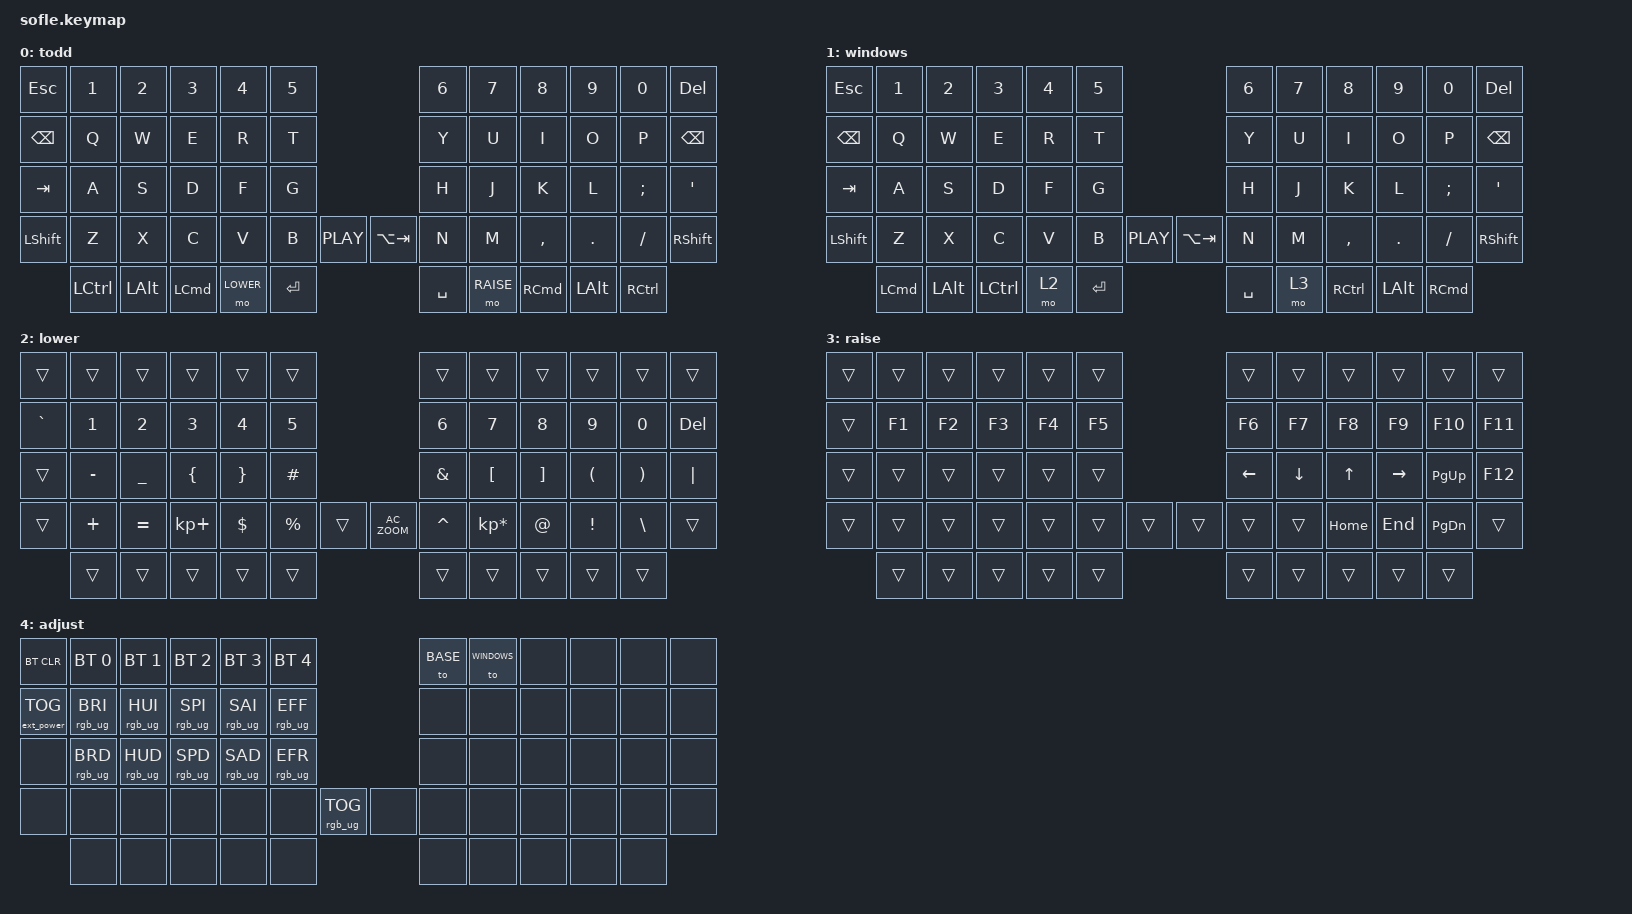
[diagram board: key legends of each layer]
/*
 * Copyright (c) 2020 The ZMK Contributors
 *
 * SPDX-License-Identifier: MIT
 */

#define BASE 0
#define WINDOWS 1
#define LOWER 2
#define RAISE 3
#define ADJUST 4

/*
 * Temporarily here because nice nano v2 spi is not defined on ZMK Yet
 * Source: https://github.com/zmkfirmware/zmk/blob/main/app/boards/shields/reviung41/boards/nice_nano.overlay
 * GitHub Issue: https://github.com/zmkfirmware/zmk/issues/885
 */

#include <dt-bindings/led/led.h>
#include <behaviors.dtsi>
#include <dt-bindings/zmk/bt.h>
#include <dt-bindings/zmk/ext_power.h>
#include <dt-bindings/zmk/keys.h>
#include <dt-bindings/zmk/rgb.h>

&pinctrl {
    spi3_default: spi3_default {
        group1 { psels = <NRF_PSEL(SPIM_MOSI, 0, 8)>; };
    };

    spi3_sleep: spi3_sleep {
        group1 {
            psels = <NRF_PSEL(SPIM_MOSI, 0, 8)>;
            low-power-enable;
        };
    };
};

&spi3 {
    compatible = "nordic,nrf-spim";
    status = "okay";
    pinctrl-0 = <&spi3_default>;
    pinctrl-1 = <&spi3_sleep>;
    pinctrl-names = "default", "sleep";

    led_strip: ws2812@0 {
        compatible = "worldsemi,ws2812-spi";
        label = "WS2812";

        /* SPI */

        reg = <0>; /* ignored, but necessary for SPI bindings */
        spi-max-frequency = <4000000>;

        /* WS2812 */

        chain-length = <30>;
        spi-one-frame = <0x70>;
        spi-zero-frame = <0x40>;
        color-mapping = <LED_COLOR_ID_GREEN LED_COLOR_ID_RED LED_COLOR_ID_BLUE>;
    };
};

/ {
    chosen { zmk,underglow = &led_strip; };
};

/* END temporary RGB support section */

/ {
    // Activate ADJUST layer by pressing raise and lower

    conditional_layers {
        compatible = "zmk,conditional-layers";

        adjust_layer {
            if-layers = <2 3>;
            then-layer = <4>;
        };
    };

    macros {
        zoomOut: zoomOut {
            compatible = "zmk,behavior-macro";
            #binding-cells = <0>;
            bindings = <&kp RIGHT_GUI &kp MINUS>;
            label = "ZOOMOUT";
        };

        zoomIn: zoomIn {
            compatible = "zmk,behavior-macro";
            #binding-cells = <0>;
            bindings = <&kp RIGHT_GUI &kp EQUAL>;
            label = "ZOOMIN";
        };
    };

    keymap {
        compatible = "zmk,keymap";

        default_layer {
            display-name = "todd";
            bindings = <
// ╭────────────────────────┬────────────────────────┬────────────────────────┬────────────────────────┬────────────────────────┬────────────────────────╮                                ╭────────────────────────┬────────────────────────┬────────────────────────┬────────────────────────┬────────────────────────┬────────────────────────╮
    &kp ESCAPE               &kp N1                   &kp N2                   &kp N3                   &kp N4                   &kp N5                                                    &kp N6                   &kp N7                   &kp N8                   &kp N9                   &kp N0                   &kp DEL
// ├────────────────────────┼────────────────────────┼────────────────────────┼────────────────────────┼────────────────────────┼────────────────────────┤                                ├────────────────────────┼────────────────────────┼────────────────────────┼────────────────────────┼────────────────────────┼────────────────────────┤
    &kp BACKSPACE            &kp Q                    &kp W                    &kp E                    &kp R                    &kp T                                                     &kp Y                    &kp U                    &kp I                    &kp O                    &kp P                    &kp BSPC
// ├────────────────────────┼────────────────────────┼────────────────────────┼────────────────────────┼────────────────────────┼────────────────────────┤                                ├────────────────────────┼────────────────────────┼────────────────────────┼────────────────────────┼────────────────────────┼────────────────────────┤
    &kp TAB                  &kp A                    &kp S                    &kp D                    &kp F                    &kp G                                                     &kp H                    &kp J                    &kp K                    &kp L                    &kp SEMI                 &kp SQT
// ├────────────────────────┼────────────────────────┼────────────────────────┼────────────────────────┼────────────────────────┼────────────────────────┤ ╭────────────╮  ╭────────────╮ ├────────────────────────┼────────────────────────┼────────────────────────┼────────────────────────┼────────────────────────┼────────────────────────┤
    &kp LSHFT                &kp Z                    &kp X                    &kp C                    &kp V                    &kp B                      &kp C_PLAY      &kp LA(TAB)    &kp N                    &kp M                    &kp COMMA                &kp DOT                  &kp FSLH                 &kp RSHFT
// ╰────────────────────────┼────────────────────────┼────────────────────────┼────────────────────────┼────────────────────────┼────────────────────────┤ ╰────────────╯  ╰────────────╯ ├────────────────────────┼────────────────────────┼────────────────────────┼────────────────────────┼────────────────────────┼────────────────────────╯
                             &kp LEFT_CONTROL         &kp LALT                 &kp LEFT_COMMAND         &mo LOWER                &kp RET                                                   &kp SPACE                &mo RAISE                &kp RIGHT_COMMAND        &kp LALT                 &kp RIGHT_CONTROL
//                          ╰────────────────────────┴────────────────────────┴────────────────────────┴────────────────────────┴────────────────────────╯                                ╰────────────────────────┴────────────────────────┴────────────────────────┴────────────────────────┴────────────────────────╯
            >;

            sensor-bindings =
                <&inc_dec_kp C_VOL_UP C_VOL_DN>,
                <&inc_dec_kp LG(LS(TAB)) LG(TAB)>;
        };

        windows {
            display-name = "windows";
            bindings = <
// ╭────────────────────────┬────────────────────────┬────────────────────────┬────────────────────────┬────────────────────────┬────────────────────────╮                                ╭────────────────────────┬────────────────────────┬────────────────────────┬────────────────────────┬────────────────────────┬────────────────────────╮
    &kp ESCAPE               &kp N1                   &kp N2                   &kp N3                   &kp N4                   &kp N5                                                    &kp N6                   &kp N7                   &kp N8                   &kp N9                   &kp N0                   &kp DEL
// ├────────────────────────┼────────────────────────┼────────────────────────┼────────────────────────┼────────────────────────┼────────────────────────┤                                ├────────────────────────┼────────────────────────┼────────────────────────┼────────────────────────┼────────────────────────┼────────────────────────┤
    &kp BACKSPACE            &kp Q                    &kp W                    &kp E                    &kp R                    &kp T                                                     &kp Y                    &kp U                    &kp I                    &kp O                    &kp P                    &kp BSPC
// ├────────────────────────┼────────────────────────┼────────────────────────┼────────────────────────┼────────────────────────┼────────────────────────┤                                ├────────────────────────┼────────────────────────┼────────────────────────┼────────────────────────┼────────────────────────┼────────────────────────┤
    &kp TAB                  &kp A                    &kp S                    &kp D                    &kp F                    &kp G                                                     &kp H                    &kp J                    &kp K                    &kp L                    &kp SEMI                 &kp SQT
// ├────────────────────────┼────────────────────────┼────────────────────────┼────────────────────────┼────────────────────────┼────────────────────────┤ ╭────────────╮  ╭────────────╮ ├────────────────────────┼────────────────────────┼────────────────────────┼────────────────────────┼────────────────────────┼────────────────────────┤
    &kp LSHFT                &kp Z                    &kp X                    &kp C                    &kp V                    &kp B                      &kp C_PLAY      &kp LA(TAB)    &kp N                    &kp M                    &kp COMMA                &kp DOT                  &kp FSLH                 &kp RSHFT
// ╰────────────────────────┼────────────────────────┼────────────────────────┼────────────────────────┼────────────────────────┼────────────────────────┤ ╰────────────╯  ╰────────────╯ ├────────────────────────┼────────────────────────┼────────────────────────┼────────────────────────┼────────────────────────┼────────────────────────╯
                             &kp LEFT_COMMAND         &kp LALT                 &kp LEFT_CONTROL         &mo 2                    &kp RET                                                   &kp SPACE                &mo 3                    &kp RIGHT_CONTROL        &kp LALT                 &kp RIGHT_COMMAND
//                          ╰────────────────────────┴────────────────────────┴────────────────────────┴────────────────────────┴────────────────────────╯                                ╰────────────────────────┴────────────────────────┴────────────────────────┴────────────────────────┴────────────────────────╯
            >;

            sensor-bindings =
                <&inc_dec_kp C_VOLUME_UP C_VOLUME_DOWN>,
                <&inc_dec_kp LA(LS(TAB)) LA(TAB)>;
        };

        LOW {
            display-name = "lower";
            bindings = <
// ╭────────────────────────┬────────────────────────┬────────────────────────┬────────────────────────┬────────────────────────┬────────────────────────╮                                ╭────────────────────────┬────────────────────────┬────────────────────────┬────────────────────────┬────────────────────────┬────────────────────────╮
    &trans                   &trans                   &trans                   &trans                   &trans                    &trans                                                   &trans                   &trans                   &trans                   &trans                   &trans                   &trans
// ├────────────────────────┼────────────────────────┼────────────────────────┼────────────────────────┼────────────────────────┼────────────────────────┤                                ├────────────────────────┼────────────────────────┼────────────────────────┼────────────────────────┼────────────────────────┼────────────────────────┤
    &kp GRAVE                &kp N1                   &kp N2                   &kp N3                   &kp N4                    &kp N5                                                   &kp N6                   &kp N7                   &kp N8                   &kp N9                   &kp N0                   &kp DEL
// ├────────────────────────┼────────────────────────┼────────────────────────┼────────────────────────┼────────────────────────┼────────────────────────┤                                ├────────────────────────┼────────────────────────┼────────────────────────┼────────────────────────┼────────────────────────┼────────────────────────┤
    &trans                   &kp MINUS                &kp UNDER                &kp LEFT_BRACE           &kp RIGHT_BRACE           &kp HASH                                                 &kp AMPS                 &kp LBKT                 &kp RBKT                 &kp LPAR                 &kp RPAR                 &kp PIPE
// ├────────────────────────┼────────────────────────┼────────────────────────┼────────────────────────┼────────────────────────┼────────────────────────┤ ╭────────────╮  ╭────────────╮ ├────────────────────────┼────────────────────────┼────────────────────────┼────────────────────────┼────────────────────────┼────────────────────────┤
    &trans                   &kp PLUS                 &kp EQUAL                &kp KP_PLUS              &kp DOLLAR                &kp PRCNT                 &trans          &kp C_AC_ZOOM  &kp CARET                &kp KP_MULTIPLY          &kp AT                   &kp EXCL                 &kp BSLH                 &trans
// ╰────────────────────────┼────────────────────────┼────────────────────────┼────────────────────────┼────────────────────────┼────────────────────────┤ ╰────────────╯  ╰────────────╯ ├────────────────────────┼────────────────────────┼────────────────────────┼────────────────────────┼────────────────────────┼────────────────────────╯
                             &trans                   &trans                   &trans                   &trans                   &trans                                                    &trans                   &trans                   &trans                   &trans                   &trans
//                          ╰────────────────────────┴────────────────────────┴────────────────────────┴────────────────────────┴────────────────────────╯                                ╰────────────────────────┴────────────────────────┴────────────────────────┴────────────────────────┴────────────────────────╯
            >;

            sensor-bindings =
                <&inc_dec_kp C_VOL_UP C_VOL_DN>,
                <&inc_dec_kp LA(TAB) LA(LS(TAB))>;
        };

        HIGH {
            display-name = "raise";
            bindings = <
// ╭────────────────────────┬────────────────────────┬────────────────────────┬────────────────────────┬────────────────────────┬────────────────────────╮                                ╭────────────────────────┬────────────────────────┬────────────────────────┬────────────────────────┬────────────────────────┬────────────────────────╮
    &trans                   &trans                   &trans                   &trans                   &trans                   &trans                                                    &trans                   &trans                   &trans                   &trans                   &trans                   &trans
// ├────────────────────────┼────────────────────────┼────────────────────────┼────────────────────────┼────────────────────────┼────────────────────────┤                                ├────────────────────────┼────────────────────────┼────────────────────────┼────────────────────────┼────────────────────────┼────────────────────────┤
    &trans                   &kp F1                   &kp F2                   &kp F3                   &kp F4                   &kp F5                                                    &kp F6                   &kp F7                   &kp F8                   &kp F9                   &kp F10                  &kp F11
// ├────────────────────────┼────────────────────────┼────────────────────────┼────────────────────────┼────────────────────────┼────────────────────────┤                                ├────────────────────────┼────────────────────────┼────────────────────────┼────────────────────────┼────────────────────────┼────────────────────────┤
    &trans                   &trans                   &trans                   &trans                   &trans                   &trans                                                    &kp LEFT                 &kp DOWN                 &kp UP                   &kp RIGHT                &kp PAGE_UP              &kp F12
// ├────────────────────────┼────────────────────────┼────────────────────────┼────────────────────────┼────────────────────────┼────────────────────────┤ ╭────────────╮  ╭────────────╮ ├────────────────────────┼────────────────────────┼────────────────────────┼────────────────────────┼────────────────────────┼────────────────────────┤
    &trans                   &trans                   &trans                   &trans                   &trans                   &trans                     &trans          &trans         &trans                   &trans                   &kp HOME                 &kp END                  &kp PAGE_DOWN            &trans
// ╰────────────────────────┼────────────────────────┼────────────────────────┼────────────────────────┼────────────────────────┼────────────────────────┤ ╰────────────╯  ╰────────────╯ ├────────────────────────┼────────────────────────┼────────────────────────┼────────────────────────┼────────────────────────┼────────────────────────╯
                             &trans                   &trans                   &trans                   &trans                   &trans                                                    &trans                   &trans                   &trans                   &trans                   &trans
//                          ╰────────────────────────┴────────────────────────┴────────────────────────┴────────────────────────┴────────────────────────╯                                ╰────────────────────────┴────────────────────────┴────────────────────────┴────────────────────────┴────────────────────────╯
            >;

            sensor-bindings = <&inc_dec_kp LG(PLUS) LG(MINUS)>;
        };

        ADJUST {
            display-name = "adjust";
            bindings = <
/ ╭────────────────────────┬────────────────────────┬────────────────────────┬────────────────────────┬────────────────────────┬────────────────────────╮                                ╭────────────────────────┬────────────────────────┬────────────────────────┬────────────────────────┬────────────────────────┬────────────────────────╮
    &bt BT_CLR               &bt BT_SEL 0             &bt BT_SEL 1             &bt BT_SEL 2             &bt BT_SEL 3             &bt BT_SEL 4                                              &to BASE                 &to WINDOWS              &none                    &none                    &none                    &none
// ├────────────────────────┼────────────────────────┼────────────────────────┼────────────────────────┼────────────────────────┼────────────────────────┤                                ├────────────────────────┼────────────────────────┼────────────────────────┼────────────────────────┼────────────────────────┼────────────────────────┤
    &ext_power EP_TOG        &rgb_ug RGB_BRI          &rgb_ug RGB_HUI          &rgb_ug RGB_SPI          &rgb_ug RGB_SAI          &rgb_ug RGB_EFF                                           &none                    &none                    &none                    &none                    &none                    &none
// ├────────────────────────┼────────────────────────┼────────────────────────┼────────────────────────┼────────────────────────┼────────────────────────┤                                ├────────────────────────┼────────────────────────┼────────────────────────┼────────────────────────┼────────────────────────┼────────────────────────┤
    &none                    &rgb_ug RGB_BRD          &rgb_ug RGB_HUD          &rgb_ug RGB_SPD          &rgb_ug RGB_SAD          &rgb_ug RGB_EFR                                           &none                    &none                    &none                    &none                    &none                    &none
// ├────────────────────────┼────────────────────────┼────────────────────────┼────────────────────────┼────────────────────────┼────────────────────────┤ ╭────────────╮  ╭────────────╮ ├────────────────────────┼────────────────────────┼────────────────────────┼────────────────────────┼────────────────────────┼────────────────────────┤
    &none                    &none                    &none                    &none                    &none                    &none                      &rgb_ug RGB_TOG &none          &none                    &none                    &none                    &none                    &none                    &none
// ╰────────────────────────┼────────────────────────┼────────────────────────┼────────────────────────┼────────────────────────┼────────────────────────┤ ╰────────────╯  ╰────────────╯ ├────────────────────────┼────────────────────────┼────────────────────────┼────────────────────────┼────────────────────────┼────────────────────────╯
                             &none                    &none                    &none                    &none                    &none                                                     &none                    &none                    &none                    &none                     &none
//                          ╰────────────────────────┴────────────────────────┴────────────────────────┴────────────────────────┴────────────────────────╯                                ╰────────────────────────┴────────────────────────┴────────────────────────┴────────────────────────┴────────────────────────╯
            >;
        };
    };
};
